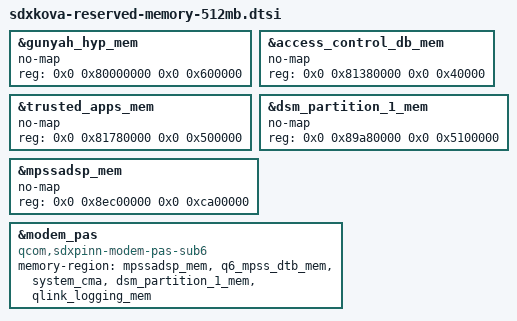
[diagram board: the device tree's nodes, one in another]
// SPDX-License-Identifier: BSD-3-Clause
/*
 * Copyright (c) Qualcomm Technologies, Inc. and/or its subsidiaries.
 */

#include "sdxkova-reserved-memory.dtsi"

&gunyah_hyp_mem {
	no-map;
	reg = <0x0 0x80000000 0x0 0x600000>;
};

&access_control_db_mem {
	no-map;
	reg = <0x0 0x81380000 0x0 0x40000>;
};

/* HYP elf package region at 0x80600000 to be shared with Linux */

&trusted_apps_mem {
	no-map;
	reg = <0x0 0x81780000 0x0 0x500000>;
};

&dsm_partition_1_mem {
	no-map;
	reg = <0x0 0x89a80000 0x0 0x5100000>;
};

/delete-node/ &dsm_partition_2_mem;

&mpssadsp_mem {
	no-map;
	reg = <0x0 0x8ec00000 0x0 0xca00000>;
};

&modem_pas {
/delete-property/ compatible;
/delete-property/ memory-region;

	compatible = "qcom,sdxpinn-modem-pas-sub6";

	memory-region = <&mpssadsp_mem>,
			<&q6_mpss_dtb_mem>,
			<&system_cma>,
			<&dsm_partition_1_mem>,
			<&qlink_logging_mem>;
};
